# S32M24x register map
Vendor: NXP Semiconductors; File version: 1.5
CPU: CM4 r0p1, little endian, MPU, FPU, VTOR, 4 interrupt priority bits
Registers are 32-bit, read-write, reset 0x0 unless marked. A register's access mark holds for its fields unless they carry their own. Offsets are from the block's base; [hi:lo] are bit positions; {n}, {i} and the like mark numbered series.

## ERM
Base 0x40018000
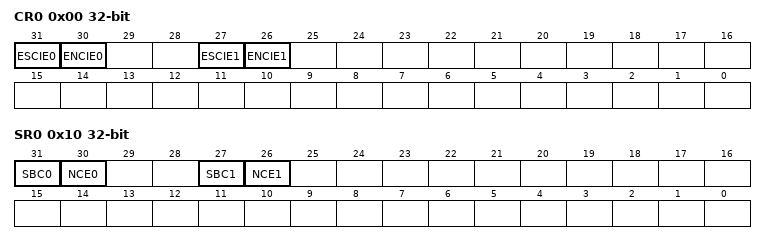
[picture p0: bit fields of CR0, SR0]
0x00 CR0 — ERM Configuration Register 0
  [31] ESCIE0
    0=Interrupt notification of Memory 0 single-bit correction events is disabled; 1=Interrupt notification of Memory 0 single-bit correction events is enabled
  [30] ENCIE0
    0=Interrupt notification of Memory 0 non-correctable error events is disabled; 1=Interrupt notification of Memory 0 non-correctable error events is enabled
  [27] ESCIE1
    0=Interrupt notification of Memory 1 single-bit correction events is disabled; 1=Interrupt notification of Memory 1 single-bit correction events is enabled
  [26] ENCIE1
    0=Interrupt notification of Memory 1 non-correctable error events is disabled; 1=Interrupt notification of Memory 1 non-correctable error events is enabled
0x10 SR0 write-1-clears — ERM Status Register 0
  [31] SBC0 write-1-clears
    0=No single-bit correction event on Memory 0 detected; 1=Single-bit correction event on Memory 0 detected
  [30] NCE0 write-1-clears
    0=No non-correctable error event on Memory 0 detected; 1=Non-correctable error event on Memory 0 detected
  [27] SBC1 write-1-clears
    0=No single-bit correction event on Memory 1 detected; 1=Single-bit correction event on Memory 1 detected
  [26] NCE1 write-1-clears
    0=No non-correctable error event on Memory 1 detected; 1=Non-correctable error event on Memory 1 detected
0x100 EAR0 ro — ERM Memory n Error Address Register
  [31:0] EAR
0x110 EAR1 ro — ERM Memory n Error Address Register
  [31:0] EAR

## EIM
Base 0x40019000
0x00 EIMCR — Error Injection Module Configuration Register
  [0] GEIEN — Global Error Injection Enable
    0=Disabled; 1=Enabled
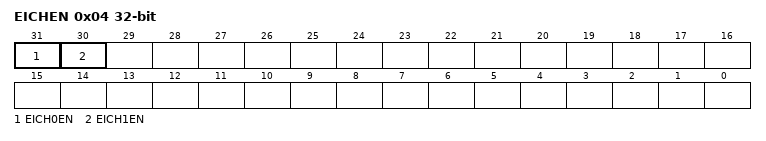
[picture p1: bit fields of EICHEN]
0x04 EICHEN — Error Injection Channel Enable register
  [31] EICH0EN — Error Injection Channel 0 Enable
    0=Error injection is disabled on Error Injection Channel 0; 1=Error injection is enabled on Error Injection Channel 0
  [30] EICH1EN — Error Injection Channel 1 Enable
    0=Error injection is disabled on Error Injection Channel 1; 1=Error injection is enabled on Error Injection Channel 1
0x100 EICHD0_WORD0 — Error Injection Channel Descriptor n, Word0
  [31:25] CHKBIT_MASK — Checkbit Mask
0x104 EICHD0_WORD1 — Error Injection Channel Descriptor n, Word1
  [31:0] B0_3DATA_MASK — Data Mask Bytes 0-3
0x140 EICHD1_WORD0 — Error Injection Channel Descriptor n, Word0
  [31:25] CHKBIT_MASK — Checkbit Mask
0x144 EICHD1_WORD1 — Error Injection Channel Descriptor n, Word1
  [31:0] B0_3DATA_MASK — Data Mask Bytes 0-3

## DMAMUX
Base 0x40021000
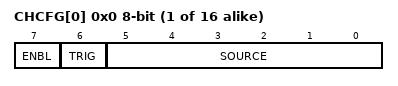
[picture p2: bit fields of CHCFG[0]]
{0x0+i} CHCFG[{i}] (i=0..15) 8-bit — Channel Configuration register
  [7] ENBL — DMA Channel Enable
    0=DMA channel is disabled. This mode is primarily used during configuration of the DMAMux. The DMA has separate channel enables/disables, which should be used to disable or reconfigure a DMA channel.; 1=DMA channel is enabled
  [6] TRIG — DMA Channel Trigger Enable
    0=Triggering is disabled. If triggering is disabled and ENBL is set, the DMA Channel will simply route the specified source to the DMA channel. (Normal mode); 1=Triggering is enabled. If triggering is enabled and ENBL is set, the DMAMUX is in Periodic Trigger mode.
  [5:0] SOURCE — DMA Channel Source (Slot)

## PDB1 — PDB
Base 0x40031000
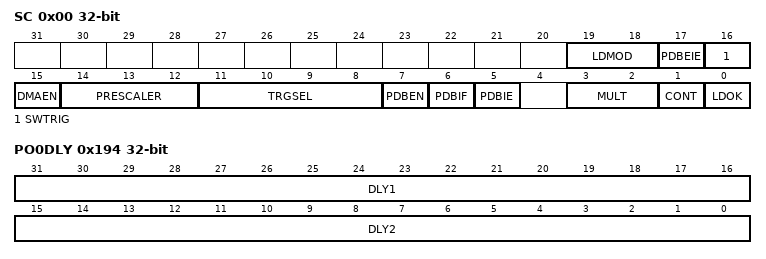
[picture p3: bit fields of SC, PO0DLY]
0x00 SC — Status and Control register
  [19:18] LDMOD — Load Mode Select
    0=The internal registers are loaded with the values from their buffers, immediately after 1 is written to LDOK; 1=The internal registers are loaded with the values from their buffers when the PDB counter (CNT) = MOD + 1 CNT delay elapsed, after 1 is written to LDOK; 2=The internal registers are loaded with the values from their buffers when a trigger input event is detected, after 1 is written to LDOK; 3=The internal registers are loaded with the values from their buffers when either the PDB counter (CNT) = MOD + 1 CNT delay elapsed, or a trigger input event is detected, after 1 is written to LDOK
  [17] PDBEIE — PDB Sequence Error Interrupt Enable
    0=PDB sequence error interrupt disabled; 1=PDB sequence error interrupt enabled
  [16] SWTRIG — Software Trigger
  [15] DMAEN — DMA Enable
    0=DMA disabled; 1=DMA enabled
  [14:12] PRESCALER — Prescaler Divider Select
    0=Counting uses the peripheral clock divided by MULT (the multiplication factor); 1=Counting uses the peripheral clock divided by 2 x MULT (the multiplication factor); 2=Counting uses the peripheral clock divided by 4 x MULT (the multiplication factor); 3=Counting uses the peripheral clock divided by 8 x MULT (the multiplication factor); 4=Counting uses the peripheral clock divided by 16 x MULT (the multiplication factor); 5=Counting uses the peripheral clock divided by 32 x MULT (the multiplication factor); 6=Counting uses the peripheral clock divided by 64 x MULT (the multiplication factor); 7=Counting uses the peripheral clock divided by 128 x MULT (the multiplication factor)
  [11:8] TRGSEL — Trigger Input Source Select
    {v}=Trigger-In {v} is selected (v=0..14); 15=Software trigger is selected
  [7] PDBEN — PDB Enable
    0=PDB disabled. Counter is off.; 1=PDB enabled
  [6] PDBIF — PDB Interrupt Flag
  [5] PDBIE — PDB Interrupt Enable
    0=PDB interrupt disabled; 1=PDB interrupt enabled
  [3:2] MULT — Multiplication Factor Select for Prescaler
    0=Multiplication factor is 1; 1=Multiplication factor is 10; 2=Multiplication factor is 20; 3=Multiplication factor is 40
  [1] CONT — Continuous Mode Enable
    0=PDB operation in One-Shot mode; 1=PDB operation in Continuous mode
  [0] LDOK — Load OK
0x04 MOD reset 0xFFFF — Modulus register
  [15:0] MOD — PDB Modulus
0x08 CNT ro — Counter register
  [15:0] CNT — PDB Counter
0x0C IDLY reset 0xFFFF — Interrupt Delay register
  [15:0] IDLY — PDB Interrupt Delay
0x190 POEN — Pulse-Out n Enable register
  [7:0] POEN — PDB Pulse-Out Enable
    0=PDB Pulse-Out disabled; 1=PDB Pulse-Out enabled
0x194 PO0DLY — Pulse-Out n Delay register
  [31:16] DLY1 — PDB Pulse-Out Delay 1
  [15:0] DLY2 — PDB Pulse-Out Delay 2
